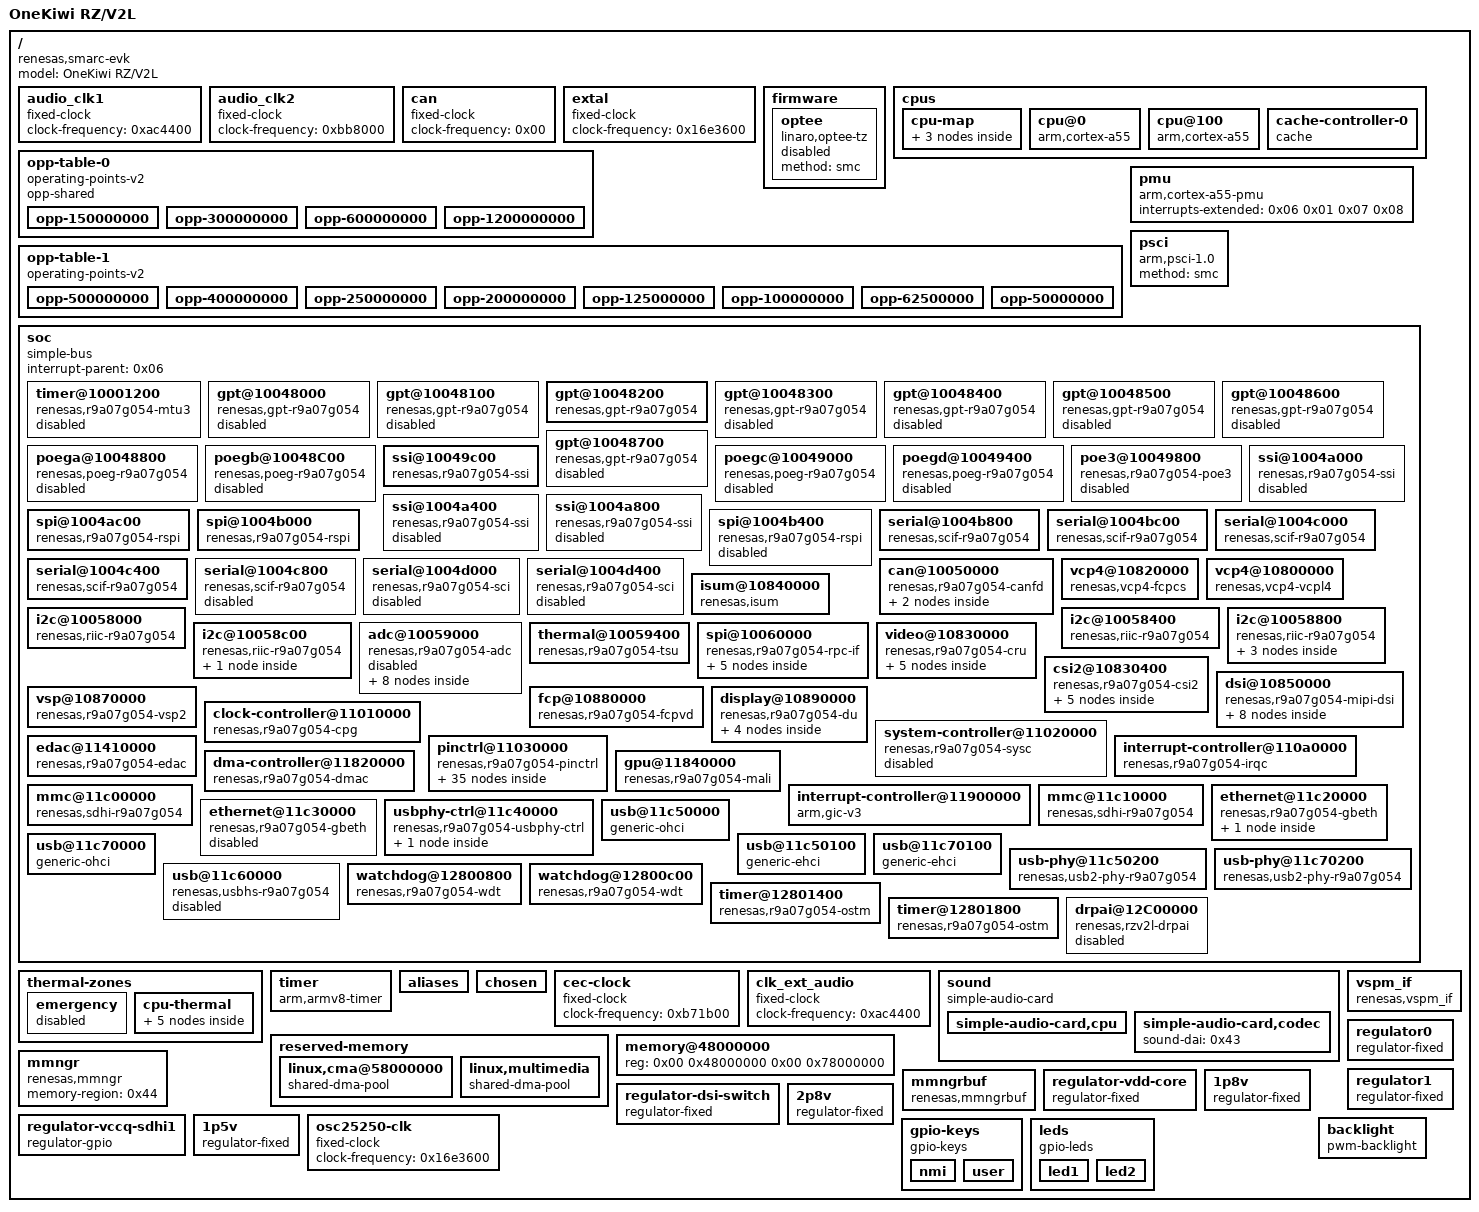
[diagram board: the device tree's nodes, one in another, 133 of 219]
/dts-v1/;

/ {
	compatible = "renesas,smarc-evk", "renesas,r9a07g054l2", "renesas,r9a07g054";
	#address-cells = <0x02>;
	#size-cells = <0x02>;
	model = "OneKiwi RZ/V2L";

	audio_clk1 {
		compatible = "fixed-clock";
		#clock-cells = <0x00>;
		clock-frequency = <0xac4400>;
		phandle = <0x08>;
	};

	audio_clk2 {
		compatible = "fixed-clock";
		#clock-cells = <0x00>;
		clock-frequency = <0xbb8000>;
		phandle = <0x09>;
	};

	can {
		compatible = "fixed-clock";
		#clock-cells = <0x00>;
		clock-frequency = <0x00>;
		phandle = <0x12>;
	};

	extal {
		compatible = "fixed-clock";
		#clock-cells = <0x00>;
		clock-frequency = <0x16e3600>;
		phandle = <0x2d>;
	};

	firmware {

		optee {
			compatible = "linaro,optee-tz";
			method = "smc";
			status = "disabled";
		};
	};

	opp-table-0 {
		compatible = "operating-points-v2";
		opp-shared;
		phandle = <0x05>;

		opp-150000000 {
			opp-hz = <0x00 0x8f0d180>;
			opp-microvolt = <0x10c8e0>;
			clock-latency-ns = <0x493e0>;
		};

		opp-300000000 {
			opp-hz = <0x00 0x11e1a300>;
			opp-microvolt = <0x10c8e0>;
			clock-latency-ns = <0x493e0>;
		};

		opp-600000000 {
			opp-hz = <0x00 0x23c34600>;
			opp-microvolt = <0x10c8e0>;
			clock-latency-ns = <0x493e0>;
		};

		opp-1200000000 {
			opp-hz = <0x00 0x47868c00>;
			opp-microvolt = <0x10c8e0>;
			clock-latency-ns = <0x493e0>;
			opp-suspend;
		};
	};

	cpus {
		#address-cells = <0x01>;
		#size-cells = <0x00>;

		cpu-map {

			cluster0 {

				core0 {
					cpu = <0x01>;
				};

				core1 {
					cpu = <0x02>;
				};
			};
		};

		cpu@0 {
			compatible = "arm,cortex-a55";
			reg = <0x00>;
			device_type = "cpu";
			#cooling-cells = <0x02>;
			next-level-cache = <0x03>;
			enable-method = "psci";
			clocks = <0x04 0x00 0x00>;
			operating-points-v2 = <0x05>;
			phandle = <0x01>;
		};

		cpu@100 {
			compatible = "arm,cortex-a55";
			reg = <0x100>;
			device_type = "cpu";
			next-level-cache = <0x03>;
			enable-method = "psci";
			clocks = <0x04 0x00 0x00>;
			operating-points-v2 = <0x05>;
			phandle = <0x02>;
		};

		cache-controller-0 {
			compatible = "cache";
			cache-unified;
			cache-size = <0x40000>;
			phandle = <0x03>;
		};
	};

	opp-table-1 {
		compatible = "operating-points-v2";
		phandle = <0x2f>;

		opp-500000000 {
			opp-hz = <0x00 0x1dcd6500>;
			opp-microvolt = <0x10c8e0>;
		};

		opp-400000000 {
			opp-hz = <0x00 0x17d78400>;
			opp-microvolt = <0x10c8e0>;
		};

		opp-250000000 {
			opp-hz = <0x00 0xee6b280>;
			opp-microvolt = <0x10c8e0>;
		};

		opp-200000000 {
			opp-hz = <0x00 0xbebc200>;
			opp-microvolt = <0x10c8e0>;
		};

		opp-125000000 {
			opp-hz = <0x00 0x7735940>;
			opp-microvolt = <0x10c8e0>;
		};

		opp-100000000 {
			opp-hz = <0x00 0x5f5e100>;
			opp-microvolt = <0x10c8e0>;
		};

		opp-62500000 {
			opp-hz = <0x00 0x3b9aca0>;
			opp-microvolt = <0x10c8e0>;
		};

		opp-50000000 {
			opp-hz = <0x00 0x2faf080>;
			opp-microvolt = <0x10c8e0>;
		};
	};

	pmu {
		compatible = "arm,cortex-a55-pmu";
		interrupts-extended = <0x06 0x01 0x07 0x08>;
	};

	psci {
		compatible = "arm,psci-1.0", "arm,psci-0.2";
		method = "smc";
	};

	soc {
		compatible = "simple-bus";
		interrupt-parent = <0x06>;
		#address-cells = <0x02>;
		#size-cells = <0x02>;
		ranges;

		timer@10001200 {
			compatible = "renesas,r9a07g054-mtu3", "renesas,rz-mtu3";
			reg = <0x00 0x10001200 0x00 0xb00>;
			interrupts = <0x00 0xaa 0x01 0x00 0xab 0x01 0x00 0xac 0x01 0x00 0xad 0x01 0x00 0xae 0x01 0x00 0xaf 0x01 0x00 0xb0 0x01 0x00 0xb1 0x01 0x00 0xb2 0x01 0x00 0xb3 0x01 0x00 0xb4 0x01 0x00 0xb5 0x01 0x00 0xb6 0x01 0x00 0xb7 0x01 0x00 0xb8 0x01 0x00 0xb9 0x01 0x00 0xba 0x01 0x00 0xbb 0x01 0x00 0xbc 0x01 0x00 0xbd 0x01 0x00 0xbe 0x01 0x00 0xbf 0x01 0x00 0xc0 0x01 0x00 0xc1 0x01 0x00 0xc2 0x01 0x00 0xc3 0x01 0x00 0xc4 0x01 0x00 0xc5 0x01 0x00 0xc6 0x01 0x00 0xc7 0x01 0x00 0xc8 0x01 0x00 0xc9 0x01 0x00 0xca 0x01 0x00 0xcb 0x01 0x00 0xcc 0x01 0x00 0xcd 0x01 0x00 0xce 0x01 0x00 0xcf 0x01 0x00 0xd0 0x01 0x00 0xd1 0x01 0x00 0xd2 0x01 0x00 0xd3 0x01 0x00 0xd4 0x01 0x00 0xd5 0x01>;
			interrupt-names = "tgia0", "tgib0", "tgic0", "tgid0", "tciv0", "tgie0", "tgif0", "tgia1", "tgib1", "tciv1", "tciu1", "tgia2", "tgib2", "tciv2", "tciu2", "tgia3", "tgib3", "tgic3", "tgid3", "tciv3", "tgia4", "tgib4", "tgic4", "tgid4", "tciv4", "tgiu5", "tgiv5", "tgiw5", "tgia6", "tgib6", "tgic6", "tgid6", "tciv6", "tgia7", "tgib7", "tgic7", "tgid7", "tciv7", "tgia8", "tgib8", "tgic8", "tgid8", "tciv8", "tciu8";
			clocks = <0x04 0x01 0x11>;
			power-domains = <0x04>;
			resets = <0x04 0x17>;
			#pwm-cells = <0x02>;
			status = "disabled";
		};

		gpt@10048000 {
			compatible = "renesas,gpt-r9a07g054", "renesas,gpt-r9a07g044";
			reg = <0x00 0x10048000 0x00 0xa4>;
			#pwm-cells = <0x02>;
			interrupts = <0x00 0xda 0x01 0x00 0xdb 0x01 0x00 0xdc 0x01 0x00 0xdd 0x01 0x00 0xde 0x01 0x00 0xdf 0x01 0x00 0xe0 0x01 0x00 0xe1 0x01 0x00 0xe2 0x01 0x00 0xe3 0x01 0x00 0xe4 0x01 0x00 0xe5 0x01 0x00 0xe6 0x01>;
			interrupt-names = "gtcia", "gtcib", "gtcic", "gtcid", "gtcie", "gtcif", "gtciada", "gtciadb", "gtciv", "gtciu", "gtcih", "gtcil", "gtdei";
			clocks = <0x04 0x01 0x13>;
			power-domains = <0x04>;
			resets = <0x04 0x19>;
			status = "disabled";
		};

		gpt@10048100 {
			compatible = "renesas,gpt-r9a07g054", "renesas,gpt-r9a07g044";
			reg = <0x00 0x10048100 0x00 0xa4>;
			#pwm-cells = <0x02>;
			interrupts = <0x00 0xe7 0x01 0x00 0xe8 0x01 0x00 0xe9 0x01 0x00 0xea 0x01 0x00 0xeb 0x01 0x00 0xec 0x01 0x00 0xed 0x01 0x00 0xee 0x01 0x00 0xef 0x01 0x00 0xf0 0x01 0x00 0xf1 0x01 0x00 0xf2 0x01 0x00 0xf3 0x01>;
			interrupt-names = "gtcia", "gtcib", "gtcic", "gtcid", "gtcie", "gtcif", "gtciada", "gtciadb", "gtciv", "gtciu", "gtcih", "gtcil", "gtdei";
			clocks = <0x04 0x01 0x13>;
			power-domains = <0x04>;
			resets = <0x04 0x19>;
			status = "disabled";
		};

		gpt@10048200 {
			compatible = "renesas,gpt-r9a07g054", "renesas,gpt-r9a07g044";
			reg = <0x00 0x10048200 0x00 0xa4>;
			#pwm-cells = <0x02>;
			interrupts = <0x00 0xf4 0x01 0x00 0xf5 0x01 0x00 0xf6 0x01 0x00 0xf7 0x01 0x00 0xf8 0x01 0x00 0xf9 0x01 0x00 0xfa 0x01 0x00 0xfb 0x01 0x00 0xfc 0x01 0x00 0xfd 0x01 0x00 0xfe 0x01 0x00 0xff 0x01 0x00 0x100 0x01>;
			interrupt-names = "gtcia", "gtcib", "gtcic", "gtcid", "gtcie", "gtcif", "gtciada", "gtciadb", "gtciv", "gtciu", "gtcih", "gtcil", "gtdei";
			clocks = <0x04 0x01 0x13>;
			power-domains = <0x04>;
			resets = <0x04 0x19>;
			status = "okay";
			pinctrl-0 = <0x07>;
			pinctrl-names = "default";
			channel = "channel_A";
			phandle = <0x45>;
		};

		gpt@10048300 {
			compatible = "renesas,gpt-r9a07g054", "renesas,gpt-r9a07g044";
			reg = <0x00 0x10048300 0x00 0xa4>;
			#pwm-cells = <0x02>;
			interrupts = <0x00 0x101 0x01 0x00 0x102 0x01 0x00 0x103 0x01 0x00 0x104 0x01 0x00 0x105 0x01 0x00 0x106 0x01 0x00 0x107 0x01 0x00 0x108 0x01 0x00 0x109 0x01 0x00 0x10a 0x01 0x00 0x10b 0x01 0x00 0x10c 0x01 0x00 0x10d 0x01>;
			interrupt-names = "gtcia", "gtcib", "gtcic", "gtcid", "gtcie", "gtcif", "gtciada", "gtciadb", "gtciv", "gtciu", "gtcih", "gtcil", "gtdei";
			clocks = <0x04 0x01 0x13>;
			power-domains = <0x04>;
			resets = <0x04 0x19>;
			status = "disabled";
		};

		gpt@10048400 {
			compatible = "renesas,gpt-r9a07g054", "renesas,gpt-r9a07g044";
			reg = <0x00 0x10048400 0x00 0xa4>;
			#pwm-cells = <0x02>;
			interrupts = <0x00 0x10e 0x01 0x00 0x10f 0x01 0x00 0x110 0x01 0x00 0x111 0x01 0x00 0x112 0x01 0x00 0x113 0x01 0x00 0x114 0x01 0x00 0x115 0x01 0x00 0x116 0x01 0x00 0x117 0x01 0x00 0x118 0x01 0x00 0x119 0x01 0x00 0x11a 0x01>;
			interrupt-names = "gtcia", "gtcib", "gtcic", "gtcid", "gtcie", "gtcif", "gtciada", "gtciadb", "gtciv", "gtciu", "gtcih", "gtcil", "gtdei";
			clocks = <0x04 0x01 0x13>;
			power-domains = <0x04>;
			resets = <0x04 0x19>;
			status = "disabled";
		};

		gpt@10048500 {
			compatible = "renesas,gpt-r9a07g054", "renesas,gpt-r9a07g044";
			reg = <0x00 0x10048500 0x00 0xa4>;
			#pwm-cells = <0x02>;
			interrupts = <0x00 0x11b 0x01 0x00 0x11c 0x01 0x00 0x11d 0x01 0x00 0x11e 0x01 0x00 0x11f 0x01 0x00 0x120 0x01 0x00 0x121 0x01 0x00 0x122 0x01 0x00 0x123 0x01 0x00 0x124 0x01 0x00 0x125 0x01 0x00 0x126 0x01 0x00 0x127 0x01>;
			interrupt-names = "gtcia", "gtcib", "gtcic", "gtcid", "gtcie", "gtcif", "gtciada", "gtciadb", "gtciv", "gtciu", "gtcih", "gtcil", "gtdei";
			clocks = <0x04 0x01 0x13>;
			power-domains = <0x04>;
			resets = <0x04 0x19>;
			status = "disabled";
		};

		gpt@10048600 {
			compatible = "renesas,gpt-r9a07g054", "renesas,gpt-r9a07g044";
			reg = <0x00 0x10048600 0x00 0xa4>;
			#pwm-cells = <0x02>;
			interrupts = <0x00 0x128 0x01 0x00 0x129 0x01 0x00 0x12a 0x01 0x00 0x12b 0x01 0x00 0x12c 0x01 0x00 0x12d 0x01 0x00 0x12e 0x01 0x00 0x12f 0x01 0x00 0x130 0x01 0x00 0x131 0x01 0x00 0x132 0x01 0x00 0x133 0x01 0x00 0x134 0x01>;
			interrupt-names = "gtcia", "gtcib", "gtcic", "gtcid", "gtcie", "gtcif", "gtciada", "gtciadb", "gtciv", "gtciu", "gtcih", "gtcil", "gtdei";
			clocks = <0x04 0x01 0x13>;
			power-domains = <0x04>;
			resets = <0x04 0x19>;
			status = "disabled";
		};

		gpt@10048700 {
			compatible = "renesas,gpt-r9a07g054", "renesas,gpt-r9a07g044";
			reg = <0x00 0x10048700 0x00 0xa4>;
			#pwm-cells = <0x02>;
			interrupts = <0x00 0x135 0x01 0x00 0x136 0x01 0x00 0x137 0x01 0x00 0x138 0x01 0x00 0x139 0x01 0x00 0x13a 0x01 0x00 0x13b 0x01 0x00 0x13c 0x01 0x00 0x13d 0x01 0x00 0x13e 0x01 0x00 0x13f 0x01 0x00 0x140 0x01 0x00 0x141 0x01>;
			interrupt-names = "gtcia", "gtcib", "gtcic", "gtcid", "gtcie", "gtcif", "gtciada", "gtciadb", "gtciv", "gtciu", "gtcih", "gtcil", "gtdei";
			clocks = <0x04 0x01 0x13>;
			power-domains = <0x04>;
			resets = <0x04 0x19>;
			status = "disabled";
		};

		poega@10048800 {
			compatible = "renesas,poeg-r9a07g054", "renesas,poeg-r9a07g044";
			reg = <0x00 0x10048800 0x00 0x04>;
			interrupts = <0x00 0x142 0x04>;
			clocks = <0x04 0x01 0x14>;
			power-domains = <0x04>;
			resets = <0x04 0x1a>;
			status = "disabled";
		};

		poegb@10048C00 {
			compatible = "renesas,poeg-r9a07g054", "renesas,poeg-r9a07g044";
			reg = <0x00 0x10048c00 0x00 0x04>;
			interrupts = <0x00 0x143 0x04>;
			clocks = <0x04 0x01 0x15>;
			power-domains = <0x04>;
			resets = <0x04 0x1b>;
			status = "disabled";
		};

		poegc@10049000 {
			compatible = "renesas,poeg-r9a07g054", "renesas,poeg-r9a07g044";
			reg = <0x00 0x10049000 0x00 0x04>;
			interrupts = <0x00 0x144 0x04>;
			clocks = <0x04 0x01 0x16>;
			power-domains = <0x04>;
			resets = <0x04 0x1c>;
			status = "disabled";
		};

		poegd@10049400 {
			compatible = "renesas,poeg-r9a07g054", "renesas,poeg-r9a07g044";
			reg = <0x00 0x10049400 0x00 0x04>;
			interrupts = <0x00 0x145 0x04>;
			clocks = <0x04 0x01 0x17>;
			power-domains = <0x04>;
			resets = <0x04 0x1d>;
			status = "disabled";
		};

		poe3@10049800 {
			compatible = "renesas,r9a07g054-poe3", "renesas,rz-poe3";
			reg = <0x00 0x10049800 0x00 0x18>;
			interrupts = <0x00 0xd6 0x04 0x00 0xd7 0x04 0x00 0xd8 0x04 0x00 0xd9 0x04>;
			interrupt-names = "oei1", "oei2", "oei3", "oei4";
			clocks = <0x04 0x01 0x12>;
			clock-names = "fck";
			resets = <0x04 0x18>;
			power-domains = <0x04>;
			status = "disabled";
		};

		ssi@10049c00 {
			compatible = "renesas,r9a07g054-ssi", "renesas,rz-ssi";
			reg = <0x00 0x10049c00 0x00 0x400>;
			interrupts = <0x00 0x146 0x04 0x00 0x147 0x01 0x00 0x148 0x01>;
			interrupt-names = "int_req", "dma_rx", "dma_tx";
			clocks = <0x04 0x01 0x3c 0x04 0x01 0x3d 0x08 0x09>;
			clock-names = "ssi", "ssi_sfr", "audio_clk1", "audio_clk2";
			resets = <0x04 0x32>;
			dmas = <0x0a 0x2655 0x0a 0x2656>;
			dma-names = "tx", "rx";
			power-domains = <0x04>;
			#sound-dai-cells = <0x00>;
			status = "okay";
			pinctrl-0 = <0x0b>;
			pinctrl-names = "default";
			phandle = <0x42>;
		};

		ssi@1004a000 {
			compatible = "renesas,r9a07g054-ssi", "renesas,rz-ssi";
			reg = <0x00 0x1004a000 0x00 0x400>;
			interrupts = <0x00 0x14a 0x04 0x00 0x14b 0x01 0x00 0x14c 0x01>;
			interrupt-names = "int_req", "dma_rx", "dma_tx";
			clocks = <0x04 0x01 0x3e 0x04 0x01 0x3f 0x08 0x09>;
			clock-names = "ssi", "ssi_sfr", "audio_clk1", "audio_clk2";
			resets = <0x04 0x33>;
			dmas = <0x0a 0x2659 0x0a 0x265a>;
			dma-names = "tx", "rx";
			power-domains = <0x04>;
			#sound-dai-cells = <0x00>;
			status = "disabled";
		};

		ssi@1004a400 {
			compatible = "renesas,r9a07g054-ssi", "renesas,rz-ssi";
			reg = <0x00 0x1004a400 0x00 0x400>;
			interrupts = <0x00 0x14e 0x04 0x00 0x151 0x01>;
			interrupt-names = "int_req", "dma_rt";
			clocks = <0x04 0x01 0x40 0x04 0x01 0x41 0x08 0x09>;
			clock-names = "ssi", "ssi_sfr", "audio_clk1", "audio_clk2";
			resets = <0x04 0x34>;
			dmas = <0x0a 0x265f>;
			dma-names = "rt";
			power-domains = <0x04>;
			#sound-dai-cells = <0x00>;
			status = "disabled";
		};

		ssi@1004a800 {
			compatible = "renesas,r9a07g054-ssi", "renesas,rz-ssi";
			reg = <0x00 0x1004a800 0x00 0x400>;
			interrupts = <0x00 0x152 0x04 0x00 0x153 0x01 0x00 0x154 0x01>;
			interrupt-names = "int_req", "dma_rx", "dma_tx";
			clocks = <0x04 0x01 0x42 0x04 0x01 0x43 0x08 0x09>;
			clock-names = "ssi", "ssi_sfr", "audio_clk1", "audio_clk2";
			resets = <0x04 0x35>;
			dmas = <0x0a 0x2661 0x0a 0x2662>;
			dma-names = "tx", "rx";
			power-domains = <0x04>;
			#sound-dai-cells = <0x00>;
			status = "disabled";
		};

		spi@1004ac00 {
			compatible = "renesas,r9a07g054-rspi", "renesas,rspi-rz";
			reg = <0x00 0x1004ac00 0x00 0x400>;
			interrupts = <0x00 0x19f 0x04 0x00 0x19d 0x04 0x00 0x19e 0x04>;
			interrupt-names = "error", "rx", "tx";
			clocks = <0x04 0x01 0x59>;
			resets = <0x04 0x49>;
			dmas = <0x0a 0x2e95 0x0a 0x2e96>;
			dma-names = "tx", "rx";
			power-domains = <0x04>;
			num-cs = <0x01>;
			#address-cells = <0x01>;
			#size-cells = <0x00>;
			status = "okay";
			pinctrl-0 = <0x0c>;
			pinctrl-names = "default";
		};

		spi@1004b000 {
			compatible = "renesas,r9a07g054-rspi", "renesas,rspi-rz";
			reg = <0x00 0x1004b000 0x00 0x400>;
			interrupts = <0x00 0x1a2 0x04 0x00 0x1a0 0x04 0x00 0x1a1 0x04>;
			interrupt-names = "error", "rx", "tx";
			clocks = <0x04 0x01 0x5a>;
			resets = <0x04 0x4a>;
			dmas = <0x0a 0x2e99 0x0a 0x2e9a>;
			dma-names = "tx", "rx";
			power-domains = <0x04>;
			num-cs = <0x01>;
			#address-cells = <0x01>;
			#size-cells = <0x00>;
			status = "okay";
			pinctrl-0 = <0x0d>;
			pinctrl-names = "default";
		};

		spi@1004b400 {
			compatible = "renesas,r9a07g054-rspi", "renesas,rspi-rz";
			reg = <0x00 0x1004b400 0x00 0x400>;
			interrupts = <0x00 0x1a5 0x04 0x00 0x1a3 0x04 0x00 0x1a4 0x04>;
			interrupt-names = "error", "rx", "tx";
			clocks = <0x04 0x01 0x5b>;
			resets = <0x04 0x4b>;
			dmas = <0x0a 0x2e9d 0x0a 0x2e9e>;
			dma-names = "tx", "rx";
			power-domains = <0x04>;
			num-cs = <0x01>;
			#address-cells = <0x01>;
			#size-cells = <0x00>;
			status = "disabled";
		};

		serial@1004b800 {
			compatible = "renesas,scif-r9a07g054", "renesas,scif-r9a07g044";
			reg = <0x00 0x1004b800 0x00 0x400>;
			interrupts = <0x00 0x17c 0x04 0x00 0x17e 0x04 0x00 0x17f 0x04 0x00 0x17d 0x04 0x00 0x180 0x04 0x00 0x180 0x04>;
			interrupt-names = "eri", "rxi", "txi", "bri", "dri", "tei";
			clocks = <0x04 0x01 0x51>;
			clock-names = "fck";
			dmas = <0x0a 0x4e79 0x0a 0x4e7a>;
			dma-names = "tx", "rx";
			power-domains = <0x04>;
			resets = <0x04 0x41>;
			status = "okay";
			pinctrl-0 = <0x0e>;
			pinctrl-names = "default";
		};

		serial@1004bc00 {
			compatible = "renesas,scif-r9a07g054", "renesas,scif-r9a07g044";
			reg = <0x00 0x1004bc00 0x00 0x400>;
			interrupts = <0x00 0x181 0x04 0x00 0x183 0x04 0x00 0x184 0x04 0x00 0x182 0x04 0x00 0x185 0x04 0x00 0x185 0x04>;
			interrupt-names = "eri", "rxi", "txi", "bri", "dri", "tei";
			clocks = <0x04 0x01 0x52>;
			clock-names = "fck";
			dmas = <0x0a 0x4e7d 0x0a 0x4e7e>;
			dma-names = "tx", "rx";
			power-domains = <0x04>;
			resets = <0x04 0x42>;
			status = "okay";
			pinctrl-0 = <0x0f>;
			pinctrl-names = "default";
		};

		serial@1004c000 {
			compatible = "renesas,scif-r9a07g054", "renesas,scif-r9a07g044";
			reg = <0x00 0x1004c000 0x00 0x400>;
			interrupts = <0x00 0x186 0x04 0x00 0x188 0x04 0x00 0x189 0x04 0x00 0x187 0x04 0x00 0x18a 0x04 0x00 0x18a 0x04>;
			interrupt-names = "eri", "rxi", "txi", "bri", "dri", "tei";
			clocks = <0x04 0x01 0x53>;
			clock-names = "fck";
			dmas = <0x0a 0x4e81 0x0a 0x4e82>;
			dma-names = "tx", "rx";
			power-domains = <0x04>;
			resets = <0x04 0x43>;
			status = "okay";
			pinctrl-0 = <0x10>;
			pinctrl-names = "default";
			uart-has-rtscts;
		};

		serial@1004c400 {
			compatible = "renesas,scif-r9a07g054", "renesas,scif-r9a07g044";
			reg = <0x00 0x1004c400 0x00 0x400>;
			interrupts = <0x00 0x18b 0x04 0x00 0x18d 0x04 0x00 0x18e 0x04 0x00 0x18c 0x04 0x00 0x18f 0x04 0x00 0x18f 0x04>;
			interrupt-names = "eri", "rxi", "txi", "bri", "dri", "tei";
			clocks = <0x04 0x01 0x54>;
			clock-names = "fck";
			dmas = <0x0a 0x4e85 0x0a 0x4e86>;
			dma-names = "tx", "rx";
			power-domains = <0x04>;
			resets = <0x04 0x44>;
			status = "okay";
			pinctrl-0 = <0x11>;
			pinctrl-names = "default";
		};

		serial@1004c800 {
			compatible = "renesas,scif-r9a07g054", "renesas,scif-r9a07g044";
			reg = <0x00 0x1004c800 0x00 0x400>;
			interrupts = <0x00 0x190 0x04 0x00 0x192 0x04 0x00 0x193 0x04 0x00 0x191 0x04 0x00 0x194 0x04 0x00 0x194 0x04>;
			interrupt-names = "eri", "rxi", "txi", "bri", "dri", "tei";
			clocks = <0x04 0x01 0x55>;
			clock-names = "fck";
			dmas = <0x0a 0x4e89 0x0a 0x4e8a>;
			dma-names = "tx", "rx";
			power-domains = <0x04>;
			resets = <0x04 0x45>;
			status = "disabled";
		};

		serial@1004d000 {
			compatible = "renesas,r9a07g054-sci", "renesas,sci";
			reg = <0x00 0x1004d000 0x00 0x400>;
			interrupts = <0x00 0x195 0x04 0x00 0x196 0x01 0x00 0x197 0x01 0x00 0x198 0x04>;
			interrupt-names = "eri", "rxi", "txi", "tei";
			clocks = <0x04 0x01 0x56>;
			clock-names = "fck";
			power-domains = <0x04>;
			resets = <0x04 0x46>;
			status = "disabled";
		};

		serial@1004d400 {
			compatible = "renesas,r9a07g054-sci", "renesas,sci";
			reg = <0x00 0x1004d400 0x00 0x400>;
			interrupts = <0x00 0x199 0x04 0x00 0x19a 0x01 0x00 0x19b 0x01 0x00 0x19c 0x04>;
			interrupt-names = "eri", "rxi", "txi", "tei";
			clocks = <0x04 0x01 0x57>;
			clock-names = "fck";
			power-domains = <0x04>;
			resets = <0x04 0x47>;
			status = "disabled";
		};

		can@10050000 {
			compatible = "renesas,r9a07g054-canfd", "renesas,rzg2l-canfd";
			reg = <0x00 0x10050000 0x00 0x8000>;
			interrupts = <0x00 0x1aa 0x04 0x00 0x1ab 0x04 0x00 0x1a6 0x04 0x00 0x1a8 0x04 0x00 0x1ac 0x04 0x00 0x1a7 0x04 0x00 0x1a9 0x04 0x00 0x1ad 0x04>;
			interrupt-names = "g_err", "g_recc", "ch0_err", "ch0_rec", "ch0_trx", "ch1_err", "ch1_rec", "ch1_trx";
			clocks = <0x04 0x01 0x5c 0x04 0x00 0x16 0x12>;
			clock-names = "fck", "canfd", "can_clk";
			assigned-clocks = <0x04 0x00 0x16>;
			assigned-clock-rates = <0x2faf080>;
			resets = <0x04 0x4c 0x04 0x4d>;
			reset-names = "rstp_n", "rstc_n";
			power-domains = <0x04>;
			status = "okay";
			pinctrl-0 = <0x13 0x14>;
			pinctrl-names = "default";

			channel0 {
				status = "okay";
			};

			channel1 {
				status = "okay";
			};
		};

		vcp4@10820000 {
			compatible = "renesas,vcp4-fcpcs";
			reg = <0x00 0x10820000 0x00 0x200>;
			renesas,#ch = <0x00>;
		};

		vcp4@10800000 {
			compatible = "renesas,vcp4-vcpl4";
			reg = <0x00 0x10800000 0x00 0x200 0x00 0x10810200 0x00 0x200>;
			interrupts = <0x00 0xa1 0x04 0x00 0xa2 0x04>;
			clocks = <0x04 0x01 0x2d 0x04 0x01 0x2e>;
			power-domains = <0x04>;
			resets = <0x04 0x29 0x04 0x2a>;
			renesas,#ch = <0x00>;
			renesas,#fcp_ch = <0x00>;
		};

		isum@10840000 {
			compatible = "renesas,isum";
			reg = <0x00 0x10840000 0x00 0x1f4>;
			interrupts = <0x00 0x9d 0x04 0x00 0x9e 0x04 0x00 0x9f 0x04 0x00 0xa0 0x04>;
			clocks = <0x04 0x01 0x2b 0x04 0x01 0x2c>;
			clock-names = "isu_aclk", "isu_pclk";
			resets = <0x04 0x27 0x04 0x28>;
			reset-names = "aresetn", "presetn";
			renesas,#ch = <0x00>;
			renesas,#rpf = <0x01>;
			renesas,#wpf = <0x01>;
			renesas,has-rs;
			power-domains = <0x04>;
		};

		i2c@10058000 {
			#address-cells = <0x01>;
			#size-cells = <0x00>;
			compatible = "renesas,riic-r9a07g054", "renesas,riic-rz";
			reg = <0x00 0x10058000 0x00 0x400>;
			interrupts = <0x00 0x15e 0x04 0x00 0x15c 0x01 0x00 0x15d 0x01 0x00 0x160 0x04 0x00 0x161 0x04 0x00 0x15f 0x04 0x00 0x162 0x04 0x00 0x163 0x04>;
			interrupt-names = "tei", "ri", "ti", "spi", "sti", "naki", "ali", "tmoi";
			clocks = <0x04 0x01 0x4d>;
			clock-frequency = <0x186a0>;
			resets = <0x04 0x3d>;
			power-domains = <0x04>;
			status = "okay";
			pinctrl-0 = <0x15>;
			pinctrl-names = "default";
		};

		i2c@10058400 {
			#address-cells = <0x01>;
			#size-cells = <0x00>;
			compatible = "renesas,riic-r9a07g054", "renesas,riic-rz";
			reg = <0x00 0x10058400 0x00 0x400>;
			interrupts = <0x00 0x166 0x04 0x00 0x164 0x01 0x00 0x165 0x01 0x00 0x168 0x04 0x00 0x169 0x04 0x00 0x167 0x04 0x00 0x16a 0x04 0x00 0x16b 0x04>;
			interrupt-names = "tei", "ri", "ti", "spi", "sti", "naki", "ali", "tmoi";
			clocks = <0x04 0x01 0x4e>;
			clock-frequency = <0x186a0>;
			resets = <0x04 0x3e>;
			power-domains = <0x04>;
			status = "okay";
			pinctrl-0 = <0x16>;
			pinctrl-names = "default";
		};

		i2c@10058800 {
			#address-cells = <0x01>;
			#size-cells = <0x00>;
			compatible = "renesas,riic-r9a07g054", "renesas,riic-rz";
			reg = <0x00 0x10058800 0x00 0x400>;
			interrupts = <0x00 0x16e 0x04 0x00 0x16c 0x01 0x00 0x16d 0x01 0x00 0x170 0x04 0x00 0x171 0x04 0x00 0x16f 0x04 0x00 0x172 0x04 0x00 0x173 0x04>;
			interrupt-names = "tei", "ri", "ti", "spi", "sti", "naki", "ali", "tmoi";
			clocks = <0x04 0x01 0x4f>;
			clock-frequency = <0x186a0>;
			resets = <0x04 0x3f>;
			power-domains = <0x04>;
			status = "okay";
			pinctrl-0 = <0x17>;
			pinctrl-names = "default";

			camera@3c {
				compatible = "ovti,ov5645";
				reg = <0x3c>;
				clocks = <0x18>;
				clock-frequency = <0x16e3600>;
				vdddo-supply = <0x19>;
				vdda-supply = <0x1a>;
				vddd-supply = <0x1b>;
				enable-gpios = <0x1c 0x59 0x00>;
				reset-gpios = <0x1c 0x60 0x01>;

				port {

					endpoint {
						clock-lanes = <0x00>;
						data-lanes = <0x01 0x02>;
						remote-endpoint = <0x1d>;
						phandle = <0x24>;
					};
				};
			};
		};

		i2c@10058c00 {
			#address-cells = <0x01>;
			#size-cells = <0x00>;
			compatible = "renesas,riic-r9a07g054", "renesas,riic-rz";
			reg = <0x00 0x10058c00 0x00 0x400>;
			interrupts = <0x00 0x176 0x04 0x00 0x174 0x01 0x00 0x175 0x01 0x00 0x178 0x04 0x00 0x179 0x04 0x00 0x177 0x04 0x00 0x17a 0x04 0x00 0x17b 0x04>;
			interrupt-names = "tei", "ri", "ti", "spi", "sti", "naki", "ali", "tmoi";
			clocks = <0x04 0x01 0x50>;
			clock-frequency = <0x186a0>;
			resets = <0x04 0x40>;
			power-domains = <0x04>;
			status = "okay";
			pinctrl-0 = <0x1e>;
			pinctrl-names = "default";

			audio-codec@a {
				#sound-dai-cells = <0x00>;
				compatible = "fsl,sgtl5000";
				reg = <0x0a>;
				VDDIO-supply = <0x1f>;
				VDDA-supply = <0x1f>;
				VDDD-supply = <0x20>;
				clocks = <0x21>;
				phandle = <0x43>;
			};
		};

		adc@10059000 {
			compatible = "renesas,r9a07g054-adc", "renesas,rzg2l-adc";
			reg = <0x00 0x10059000 0x00 0x400>;
			interrupts = <0x00 0x15b 0x01>;
			clocks = <0x04 0x01 0x5e 0x04 0x01 0x5f>;
			clock-names = "adclk", "pclk";
			resets = <0x04 0x51 0x04 0x52>;
			reset-names = "presetn", "adrst-n";
			power-domains = <0x04>;
			status = "disabled";
			#address-cells = <0x01>;
			#size-cells = <0x00>;

			channel@0 {
				reg = <0x00>;
			};

			channel@1 {
				reg = <0x01>;
			};

			channel@2 {
				reg = <0x02>;
			};

			channel@3 {
				reg = <0x03>;
			};

			channel@4 {
				reg = <0x04>;
			};

			channel@5 {
				reg = <0x05>;
			};

			channel@6 {
				reg = <0x06>;
			};

			channel@7 {
				reg = <0x07>;
			};
		};

		thermal@10059400 {
			compatible = "renesas,r9a07g054-tsu", "renesas,rzg2l-tsu";
			reg = <0x00 0x10059400 0x00 0x400>;
			clocks = <0x04 0x01 0x60>;
			resets = <0x04 0x53>;
			power-domains = <0x04>;
			#thermal-sensor-cells = <0x01>;
			phandle = <0x3f>;
		};

		spi@10060000 {
			compatible = "renesas,r9a07g054-rpc-if", "renesas,rzg2l-rpc-if";
			reg = <0x00 0x10060000 0x00 0x10000 0x00 0x20000000 0x00 0x10000000 0x00 0x10070000 0x00 0x10000>;
			reg-names = "regs", "dirmap", "wbuf";
			interrupts = <0x00 0x29 0x04>;
			clocks = <0x04 0x01 0x1e 0x04 0x01 0x1f>;
			resets = <0x04 0x21>;
			power-domains = <0x04>;
			#address-cells = <0x01>;
			#size-cells = <0x00>;
			status = "okay";
			pinctrl-0 = <0x22>;
			pinctrl-names = "default";

			flash@0 {
				compatible = "micron,mt25qu512a", "jedec,spi-nor";
				reg = <0x00>;
				m25p,fast-read;
				spi-max-frequency = <0x2faf080>;
				spi-rx-bus-width = <0x04>;
				spi-tx-bus-width = <0x04>;

				partitions {
					compatible = "fixed-partitions";
					#address-cells = <0x01>;
					#size-cells = <0x01>;

					partition@0 {
						label = "bl2";
						reg = <0x00 0x1c000>;
					};

					partition@1d000 {
						label = "fip";
						reg = <0x1d000 0x1fe3000>;
					};

					partition@2000000 {
						label = "user";
						reg = <0x2000000 0x2000000>;
					};
				};
			};
		};

		video@10830000 {
			compatible = "renesas,r9a07g054-cru", "renesas,rzg2l-cru";
			reg = <0x00 0x10830000 0x00 0x400>;
			clocks = <0x04 0x01 0x30 0x04 0x01 0x31 0x04 0x01 0x32>;
			clock-names = "video", "apb", "axi";
			interrupts = <0x00 0xa7 0x04 0x00 0xa8 0x04 0x00 0xa9 0x04>;
			interrupt-names = "image_conv", "image_conv_err", "axi_mst_err";
			resets = <0x04 0x2c 0x04 0x2d>;
			reset-names = "presetn", "aresetn";
			power-domains = <0x04>;
			status = "okay";

			ports {
				#address-cells = <0x01>;
				#size-cells = <0x00>;

				port@0 {
					#address-cells = <0x01>;
					#size-cells = <0x00>;
					reg = <0x00>;

					endpoint@0 {
						reg = <0x00>;
					};
				};

				port@1 {
					#address-cells = <0x01>;
					#size-cells = <0x00>;
					reg = <0x01>;

					endpoint@0 {
						reg = <0x00>;
						remote-endpoint = <0x23>;
						phandle = <0x25>;
					};
				};
			};
		};

		csi2@10830400 {
			compatible = "renesas,r9a07g054-csi2", "renesas,rzg2l-csi2";
			reg = <0x00 0x10830400 0x00 0xfc00>;
			interrupts = <0x00 0xa6 0x04>;
			clocks = <0x04 0x01 0x2f 0x04 0x01 0x30 0x04 0x01 0x31>;
			clock-names = "system", "video", "apb";
			resets = <0x04 0x2c 0x04 0x2b>;
			reset-names = "presetn", "cmn-rstb";
			power-domains = <0x04>;
			status = "okay";

			ports {
				#address-cells = <0x01>;
				#size-cells = <0x00>;

				port@0 {
					reg = <0x00>;

					endpoint {
						clock-lanes = <0x00>;
						data-lanes = <0x01 0x02>;
						remote-endpoint = <0x24>;
						phandle = <0x1d>;
					};
				};

				port@1 {
					#address-cells = <0x01>;
					#size-cells = <0x00>;
					reg = <0x01>;

					endpoint@0 {
						reg = <0x00>;
						remote-endpoint = <0x25>;
						phandle = <0x23>;
					};
				};
			};
		};

		dsi@10850000 {
			compatible = "renesas,r9a07g054-mipi-dsi", "renesas,rzg2l-mipi-dsi";
			reg = <0x00 0x10850000 0x00 0x20000>;
			interrupts = <0x00 0x8e 0x04 0x00 0x8f 0x04 0x00 0x90 0x04 0x00 0x91 0x04 0x00 0x92 0x04 0x00 0x93 0x04 0x00 0x94 0x04>;
			interrupt-names = "seq0", "seq1", "vin1", "rcv", "ferr", "ppi", "debug";
			clocks = <0x04 0x01 0x33 0x04 0x01 0x34 0x04 0x01 0x35 0x04 0x01 0x36 0x04 0x01 0x37 0x04 0x01 0x38>;
			clock-names = "pllclk", "sysclk", "aclk", "pclk", "vclk", "lpclk";
			resets = <0x04 0x2e 0x04 0x2f 0x04 0x30>;
			reset-names = "rst", "arst", "prst";
			power-domains = <0x04>;
			status = "okay";
			#address-cells = <0x01>;
			#size-cells = <0x00>;

			ports {
				#address-cells = <0x01>;
				#size-cells = <0x00>;

				port@0 {
					reg = <0x00>;

					endpoint {
						remote-endpoint = <0x26>;
						phandle = <0x2c>;
					};
				};

				port@1 {
					reg = <0x01>;

					endpoint {
						remote-endpoint = <0x27>;
						data-lanes = <0x01 0x02>;
						phandle = <0x29>;
					};
				};
			};

			panel@0 {
				compatible = "newhaven,nhd35-640480ef";
				reg = <0x00>;
				reset-gpios = <0x1c 0x154 0x01>;
				backlight = <0x28>;
				status = "okay";

				port {

					endpoint {
						remote-endpoint = <0x29>;
						phandle = <0x27>;
					};
				};
			};
		};

		vsp@10870000 {
			compatible = "renesas,r9a07g054-vsp2", "renesas,r9a07g044-vsp2";
			reg = <0x00 0x10870000 0x00 0x10000>;
			interrupts = <0x00 0x95 0x04>;
			clocks = <0x04 0x01 0x39 0x04 0x01 0x3a 0x04 0x01 0x3b>;
			clock-names = "aclk", "pclk", "vclk";
			power-domains = <0x04>;
			resets = <0x04 0x31>;
			renesas,fcp = <0x2a>;
			phandle = <0x2b>;
		};

		fcp@10880000 {
			compatible = "renesas,r9a07g054-fcpvd", "renesas,fcpv";
			reg = <0x00 0x10880000 0x00 0x10000>;
			clocks = <0x04 0x01 0x39 0x04 0x01 0x3a 0x04 0x01 0x3b>;
			clock-names = "aclk", "pclk", "vclk";
			power-domains = <0x04>;
			resets = <0x04 0x31>;
			phandle = <0x2a>;
		};

		display@10890000 {
			compatible = "renesas,r9a07g054-du", "renesas,r9a07g044-du";
			reg = <0x00 0x10890000 0x00 0x10000>;
			interrupts = <0x00 0x98 0x04>;
			clocks = <0x04 0x01 0x39 0x04 0x01 0x3a 0x04 0x01 0x3b>;
			clock-names = "aclk", "pclk", "vclk";
			power-domains = <0x04>;
			resets = <0x04 0x31>;
			renesas,vsps = <0x2b 0x00>;
			status = "okay";
			dsi-lanes = <0x02>;

			ports {
				#address-cells = <0x01>;
				#size-cells = <0x00>;

				port@0 {
					reg = <0x00>;

					endpoint {
						remote-endpoint = <0x2c>;
						phandle = <0x26>;
					};
				};

				port@1 {
					reg = <0x01>;
				};
			};
		};

		clock-controller@11010000 {
			compatible = "renesas,r9a07g054-cpg";
			reg = <0x00 0x11010000 0x00 0x10000>;
			clocks = <0x2d>;
			clock-names = "extal";
			#clock-cells = <0x02>;
			#reset-cells = <0x01>;
			#power-domain-cells = <0x00>;
			phandle = <0x04>;
		};

		system-controller@11020000 {
			compatible = "renesas,r9a07g054-sysc", "syscon";
			reg = <0x00 0x11020000 0x00 0x10000>;
			interrupts = <0x00 0x2a 0x04 0x00 0x2b 0x04 0x00 0x2c 0x04 0x00 0x2d 0x04>;
			interrupt-names = "lpm_int", "ca55stbydone_int", "cm33stbyr_int", "ca55_deny";
			#renesas,sysc-signal-cells = <0x02>;
			status = "disabled";
			phandle = <0x3e>;
		};

		pinctrl@11030000 {
			compatible = "renesas,r9a07g054-pinctrl", "renesas,r9a07g044-pinctrl";
			reg = <0x00 0x11030000 0x00 0x10000>;
			gpio-controller;
			#gpio-cells = <0x02>;
			#address-cells = <0x02>;
			#interrupt-cells = <0x02>;
			interrupt-parent = <0x2e>;
			interrupt-controller;
			gpio-ranges = <0x1c 0x00 0x00 0x188>;
			clocks = <0x04 0x01 0x5d>;
			power-domains = <0x04>;
			resets = <0x04 0x4e 0x04 0x4f 0x04 0x50>;
			phandle = <0x1c>;

			can0 {
				pinmux = <0x20058 0x20051>;
				phandle = <0x13>;
			};

			can1 {
				pinmux = <0x20068 0x20061>;
				phandle = <0x14>;
			};

			eth0 {
				phandle = <0x33>;

				txc {
					pinmux = <0x100a0>;
					power-source = <0x708>;
					output-enable;
				};

				mux {
					pinmux = <0x100e1 0x100d9 0x100e0 0x100a1 0x100a2 0x100a8 0x100a9 0x100b0 0x100c0 0x100c1 0x100c8 0x100c9 0x100d0 0x100d1>;
					power-source = <0x708>;
				};
			};

			gpt2 {
				pinmux = <0x30010>;
				phandle = <0x07>;
			};

			i2c0 {
				pins = "RIIC0_SDA", "RIIC0_SCL";
				input-enable;
				phandle = <0x15>;
			};

			i2c1 {
				pins = "RIIC1_SDA", "RIIC1_SCL";
				input-enable;
				phandle = <0x16>;
			};

			i2c2 {
				pinmux = <0x20019 0x20018>;
				phandle = <0x17>;
			};

			i2c3 {
				pinmux = <0x30091 0x30090>;
				phandle = <0x1e>;
			};

			scif0 {
				pinmux = <0x10130 0x10131>;
				phandle = <0x0e>;
			};

			scif1 {
				pinmux = <0x10141 0x10140>;
				phandle = <0x0f>;
			};

			scif2 {
				pinmux = <0x10183 0x10184 0x10181 0x10180>;
				phandle = <0x10>;
			};

			scif3 {
				pinmux = <0x50001 0x50000>;
				phandle = <0x11>;
			};

			sd0emmc {
				phandle = <0x31>;

				sd0_emmc_data {
					pins = "SD0_DATA0", "SD0_DATA1", "SD0_DATA2", "SD0_DATA3", "SD0_DATA4", "SD0_DATA5", "SD0_DATA6", "SD0_DATA7";
					power-source = <0x708>;
				};

				sd0_emmc_ctrl {
					pins = "SD0_CLK", "SD0_CMD";
					power-source = <0x708>;
				};

				sd0_emmc_rst {
					pins = "SD0_RST#";
					power-source = <0x708>;
				};
			};

			sd1 {
				phandle = <0x32>;

				sd1_data {
					pins = "SD1_DATA0", "SD1_DATA1", "SD1_DATA2", "SD1_DATA3";
					power-source = <0xce4>;
				};

				sd1_ctrl {
					pins = "SD1_CLK", "SD1_CMD";
					power-source = <0xce4>;
				};

				sd1_mux {
					pinmux = <0x10098>;
				};
			};

			sd1_uhs {

				sd1_data_uhs {
					pins = "SD1_DATA0", "SD1_DATA1", "SD1_DATA2", "SD1_DATA3";
					power-source = <0x708>;
				};

				sd1_ctrl_uhs {
					pins = "SD1_CLK", "SD1_CMD";
					power-source = <0x708>;
				};

				sd1_mux_uhs {
					pinmux = <0x10098>;
				};
			};

			qspi0 {
				phandle = <0x22>;

				qspi0-data {
					pins = "QSPI0_IO0", "QSPI0_IO1", "QSPI0_IO2", "QSPI0_IO3";
					power-source = <0x708>;
				};

				qspi0-ctrl {
					pins = "QSPI0_SPCLK", "QSPI0_SSL", "QSPI_RESET#";
					power-source = <0x708>;
				};
			};

			sound_clk {
				pins = "AUDIO_CLK1", "AUDIO_CLK2";
				input-enable;
			};

			spi0 {
				pinmux = <0x50178 0x5017a 0x50179 0x5017b>;
				phandle = <0x0c>;
			};

			spi1 {
				pinmux = <0x10160 0x10161 0x10162 0x10163>;
				phandle = <0x0d>;
			};

			ssi0 {
				pinmux = <0x10168 0x10169 0x1016a 0x1016b>;
				phandle = <0x0b>;
			};

			usb0 {
				pinmux = <0x10020 0x10028 0x10029>;
				phandle = <0x3b>;
			};

			usb1 {
				pinmux = <0x10150 0x10151>;
				phandle = <0x3d>;
			};
		};

		interrupt-controller@110a0000 {
			compatible = "renesas,r9a07g054-irqc", "renesas,rzg2l-irqc";
			#interrupt-cells = <0x02>;
			#address-cells = <0x00>;
			interrupt-controller;
			reg = <0x00 0x110a0000 0x00 0x10000>;
			interrupts = <0x00 0x00 0x04 0x00 0x01 0x04 0x00 0x02 0x04 0x00 0x03 0x04 0x00 0x04 0x04 0x00 0x05 0x04 0x00 0x06 0x04 0x00 0x07 0x04 0x00 0x08 0x04 0x00 0x1bc 0x04 0x00 0x1bd 0x04 0x00 0x1be 0x04 0x00 0x1bf 0x04 0x00 0x1c0 0x04 0x00 0x1c1 0x04 0x00 0x1c2 0x04 0x00 0x1c3 0x04 0x00 0x1c4 0x04 0x00 0x1c5 0x04 0x00 0x1c6 0x04 0x00 0x1c7 0x04 0x00 0x1c8 0x04 0x00 0x1c9 0x04 0x00 0x1ca 0x04 0x00 0x1cb 0x04 0x00 0x1cc 0x04 0x00 0x1cd 0x04 0x00 0x1ce 0x04 0x00 0x1cf 0x04 0x00 0x1d0 0x04 0x00 0x1d1 0x04 0x00 0x1d2 0x04 0x00 0x1d3 0x04 0x00 0x1d4 0x04 0x00 0x1d5 0x04 0x00 0x1d6 0x04 0x00 0x1d7 0x04 0x00 0x1d8 0x04 0x00 0x1d9 0x04 0x00 0x1da 0x04 0x00 0x1db 0x04 0x00 0x19 0x01 0x00 0x22 0x01 0x00 0x23 0x01 0x00 0x24 0x01 0x00 0x25 0x01 0x00 0x26 0x01 0x00 0x27 0x01>;
			interrupt-names = "nmi", "irq0", "irq1", "irq2", "irq3", "irq4", "irq5", "irq6", "irq7", "tint0", "tint1", "tint2", "tint3", "tint4", "tint5", "tint6", "tint7", "tint8", "tint9", "tint10", "tint11", "tint12", "tint13", "tint14", "tint15", "tint16", "tint17", "tint18", "tint19", "tint20", "tint21", "tint22", "tint23", "tint24", "tint25", "tint26", "tint27", "tint28", "tint29", "tint30", "tint31", "bus-err", "ec7tie1-0", "ec7tie2-0", "ec7tiovf-0", "ec7tie1-1", "ec7tie2-1", "ec7tiovf-1";
			clocks = <0x04 0x01 0x08 0x04 0x01 0x09>;
			clock-names = "clk", "pclk";
			power-domains = <0x04>;
			resets = <0x04 0x0f>;
			phandle = <0x2e>;
		};

		edac@11410000 {
			compatible = "renesas,r9a07g054-edac";
			reg = <0x00 0x11410000 0x00 0x10000>;
			interrupts = <0x00 0x28 0x04>;
			interrupt-names = "ecc_irq";
		};

		dma-controller@11820000 {
			compatible = "renesas,r9a07g054-dmac", "renesas,rz-dmac";
			reg = <0x00 0x11820000 0x00 0x10000 0x00 0x11830000 0x00 0x10000>;
			interrupts = <0x00 0x8d 0x01 0x00 0x7d 0x01 0x00 0x7e 0x01 0x00 0x7f 0x01 0x00 0x80 0x01 0x00 0x81 0x01 0x00 0x82 0x01 0x00 0x83 0x01 0x00 0x84 0x01 0x00 0x85 0x01 0x00 0x86 0x01 0x00 0x87 0x01 0x00 0x88 0x01 0x00 0x89 0x01 0x00 0x8a 0x01 0x00 0x8b 0x01 0x00 0x8c 0x01>;
			interrupt-names = "error", "ch0", "ch1", "ch2", "ch3", "ch4", "ch5", "ch6", "ch7", "ch8", "ch9", "ch10", "ch11", "ch12", "ch13", "ch14", "ch15";
			clocks = <0x04 0x01 0x0c 0x04 0x01 0x0d>;
			clock-names = "main", "register";
			power-domains = <0x04>;
			resets = <0x04 0x11 0x04 0x12>;
			reset-names = "arst", "rst_async";
			#dma-cells = <0x01>;
			dma-channels = <0x10>;
			phandle = <0x0a>;
		};

		gpu@11840000 {
			compatible = "renesas,r9a07g054-mali", "arm,mali-bifrost";
			reg = <0x00 0x11840000 0x00 0x10000>;
			interrupts = <0x00 0x9a 0x04 0x00 0x9b 0x04 0x00 0x99 0x04 0x00 0x9c 0x04>;
			interrupt-names = "job", "mmu", "gpu", "event";
			clocks = <0x04 0x01 0x28 0x04 0x01 0x29 0x04 0x01 0x2a>;
			clock-names = "gpu", "bus", "bus_ace";
			resets = <0x04 0x24 0x04 0x25 0x04 0x26>;
			reset-names = "rst", "axi_rst", "ace_rst";
			operating-points-v2 = <0x2f>;
			status = "okay";
			mali-supply = <0x30>;
		};

		interrupt-controller@11900000 {
			compatible = "arm,gic-v3";
			#interrupt-cells = <0x03>;
			#address-cells = <0x00>;
			interrupt-controller;
			reg = <0x00 0x11900000 0x00 0x40000 0x00 0x11940000 0x00 0x60000>;
			interrupts = <0x01 0x09 0x08>;
			phandle = <0x06>;
		};

		mmc@11c00000 {
			compatible = "renesas,sdhi-r9a07g054", "renesas,rcar-gen3-sdhi";
			reg = <0x00 0x11c00000 0x00 0x10000>;
			interrupts = <0x00 0x68 0x04 0x00 0x69 0x04>;
			clocks = <0x04 0x01 0x20 0x04 0x01 0x22 0x04 0x01 0x21 0x04 0x01 0x23>;
			clock-names = "core", "clkh", "cd", "aclk";
			resets = <0x04 0x22>;
			power-domains = <0x04>;
			status = "okay";
			pinctrl-names = "default", "state_uhs";
			pinctrl-0 = <0x31>;
			pinctrl-1 = <0x31>;
			vmmc-supply = <0x1f>;
			vqmmc-supply = <0x20>;
			bus-width = <0x08>;
			mmc-hs200-1_8v;
			non-removable;
			fixed-emmc-driver-type = <0x01>;
		};

		mmc@11c10000 {
			compatible = "renesas,sdhi-r9a07g054", "renesas,rcar-gen3-sdhi";
			reg = <0x00 0x11c10000 0x00 0x10000>;
			interrupts = <0x00 0x6a 0x04 0x00 0x6b 0x04>;
			clocks = <0x04 0x01 0x24 0x04 0x01 0x26 0x04 0x01 0x25 0x04 0x01 0x27>;
			clock-names = "core", "clkh", "cd", "aclk";
			resets = <0x04 0x23>;
			power-domains = <0x04>;
			status = "okay";
			pinctrl-0 = <0x32>;
			pinctrl-names = "default";
			vmmc-supply = <0x1f>;
			bus-width = <0x04>;
		};

		ethernet@11c20000 {
			compatible = "renesas,r9a07g054-gbeth", "renesas,rzg2l-gbeth";
			reg = <0x00 0x11c20000 0x00 0x10000>;
			interrupts = <0x00 0x54 0x04 0x00 0x55 0x04 0x00 0x56 0x04>;
			interrupt-names = "mux", "fil", "arp_ns";
			phy-mode = "rgmii-id";
			clocks = <0x04 0x01 0x49 0x04 0x01 0x4a 0x04 0x00 0x0e>;
			clock-names = "axi", "chi", "refclk";
			resets = <0x04 0x3b>;
			power-domains = <0x04>;
			#address-cells = <0x01>;
			#size-cells = <0x00>;
			status = "okay";
			pinctrl-0 = <0x33>;
			pinctrl-names = "default";
			phy-handle = <0x34>;

			ethernet-phy@7 {
				compatible = "ethernet-phy-id0022.1640", "ethernet-phy-ieee802.3-c22";
				reg = <0x07>;
				rxc-skew-psec = <0x960>;
				txc-skew-psec = <0x960>;
				rxdv-skew-psec = <0x00>;
				txen-skew-psec = <0x00>;
				rxd0-skew-psec = <0x00>;
				rxd1-skew-psec = <0x00>;
				rxd2-skew-psec = <0x00>;
				rxd3-skew-psec = <0x00>;
				txd0-skew-psec = <0x00>;
				txd1-skew-psec = <0x00>;
				txd2-skew-psec = <0x00>;
				txd3-skew-psec = <0x00>;
				interrupt-parent = <0x1c>;
				interrupts = <0x08 0x08>;
				phandle = <0x34>;
			};
		};

		ethernet@11c30000 {
			compatible = "renesas,r9a07g054-gbeth", "renesas,rzg2l-gbeth";
			reg = <0x00 0x11c30000 0x00 0x10000>;
			interrupts = <0x00 0x57 0x04 0x00 0x58 0x04 0x00 0x59 0x04>;
			interrupt-names = "mux", "fil", "arp_ns";
			phy-mode = "rgmii";
			clocks = <0x04 0x01 0x4b 0x04 0x01 0x4c 0x04 0x00 0x0e>;
			clock-names = "axi", "chi", "refclk";
			resets = <0x04 0x3c>;
			power-domains = <0x04>;
			#address-cells = <0x01>;
			#size-cells = <0x00>;
			status = "disabled";
		};

		usbphy-ctrl@11c40000 {
			compatible = "renesas,r9a07g054-usbphy-ctrl", "renesas,rzg2l-usbphy-ctrl";
			reg = <0x00 0x11c40000 0x00 0x10000>;
			clocks = <0x04 0x01 0x48>;
			resets = <0x04 0x3a>;
			power-domains = <0x04>;
			#reset-cells = <0x01>;
			status = "okay";
			phandle = <0x35>;

			regulator-vbus {
				regulator-name = "vbus";
				phandle = <0x3c>;
			};
		};

		usb@11c50000 {
			compatible = "generic-ohci";
			reg = <0x00 0x11c50000 0x00 0x100>;
			interrupts = <0x00 0x5b 0x04>;
			clocks = <0x04 0x01 0x48 0x04 0x01 0x45>;
			resets = <0x35 0x00 0x04 0x37>;
			phys = <0x36 0x01>;
			phy-names = "usb";
			power-domains = <0x04>;
			status = "okay";
			dr_mode = "otg";
			memory-region = <0x37>;
			phandle = <0x39>;
		};

		usb@11c70000 {
			compatible = "generic-ohci";
			reg = <0x00 0x11c70000 0x00 0x100>;
			interrupts = <0x00 0x60 0x04>;
			clocks = <0x04 0x01 0x48 0x04 0x01 0x46>;
			resets = <0x35 0x01 0x04 0x38>;
			phys = <0x38 0x01>;
			phy-names = "usb";
			power-domains = <0x04>;
			status = "okay";
			memory-region = <0x37>;
			phandle = <0x3a>;
		};

		usb@11c50100 {
			compatible = "generic-ehci";
			reg = <0x00 0x11c50100 0x00 0x100>;
			interrupts = <0x00 0x5c 0x04>;
			clocks = <0x04 0x01 0x48 0x04 0x01 0x45>;
			resets = <0x35 0x00 0x04 0x37>;
			phys = <0x36 0x02>;
			phy-names = "usb";
			companion = <0x39>;
			power-domains = <0x04>;
			status = "okay";
			dr_mode = "otg";
			memory-region = <0x37>;
		};

		usb@11c70100 {
			compatible = "generic-ehci";
			reg = <0x00 0x11c70100 0x00 0x100>;
			interrupts = <0x00 0x61 0x04>;
			clocks = <0x04 0x01 0x48 0x04 0x01 0x46>;
			resets = <0x35 0x01 0x04 0x38>;
			phys = <0x38 0x02>;
			phy-names = "usb";
			companion = <0x3a>;
			power-domains = <0x04>;
			status = "okay";
			memory-region = <0x37>;
		};

		usb-phy@11c50200 {
			compatible = "renesas,usb2-phy-r9a07g054", "renesas,rzg2l-usb2-phy";
			reg = <0x00 0x11c50200 0x00 0x700>;
			interrupts = <0x00 0x5e 0x04>;
			clocks = <0x04 0x01 0x48 0x04 0x01 0x45>;
			resets = <0x35 0x00>;
			#phy-cells = <0x01>;
			power-domains = <0x04>;
			status = "okay";
			pinctrl-0 = <0x3b>;
			pinctrl-names = "default";
			vbus-supply = <0x3c>;
			phandle = <0x36>;
		};

		usb-phy@11c70200 {
			compatible = "renesas,usb2-phy-r9a07g054", "renesas,rzg2l-usb2-phy";
			reg = <0x00 0x11c70200 0x00 0x700>;
			interrupts = <0x00 0x63 0x04>;
			clocks = <0x04 0x01 0x48 0x04 0x01 0x46>;
			resets = <0x35 0x01>;
			#phy-cells = <0x01>;
			power-domains = <0x04>;
			status = "okay";
			pinctrl-0 = <0x3d>;
			pinctrl-names = "default";
			phandle = <0x38>;
		};

		usb@11c60000 {
			compatible = "renesas,usbhs-r9a07g054", "renesas,rzg2l-usbhs";
			reg = <0x00 0x11c60000 0x00 0x10000>;
			interrupts = <0x00 0x64 0x01 0x00 0x65 0x04 0x00 0x66 0x04 0x00 0x67 0x04>;
			clocks = <0x04 0x01 0x48 0x04 0x01 0x47>;
			resets = <0x35 0x00 0x04 0x39>;
			renesas,buswait = <0x07>;
			phys = <0x36 0x03>;
			phy-names = "usb";
			power-domains = <0x04>;
			status = "disabled";
		};

		watchdog@12800800 {
			compatible = "renesas,r9a07g054-wdt", "renesas,rzg2l-wdt";
			reg = <0x00 0x12800800 0x00 0x400>;
			clocks = <0x04 0x01 0x18 0x04 0x01 0x19>;
			clock-names = "pclk", "oscclk";
			interrupts = <0x00 0x31 0x04 0x00 0x32 0x04>;
			interrupt-names = "wdt", "perrout";
			resets = <0x04 0x1e>;
			power-domains = <0x04>;
			channel,id = <0x00>;
			status = "okay";
			timeout-sec = <0x3c>;
		};

		watchdog@12800c00 {
			compatible = "renesas,r9a07g054-wdt", "renesas,rzg2l-wdt";
			reg = <0x00 0x12800c00 0x00 0x400>;
			clocks = <0x04 0x01 0x1a 0x04 0x01 0x1b>;
			clock-names = "pclk", "oscclk";
			interrupts = <0x00 0x33 0x04 0x00 0x34 0x04>;
			interrupt-names = "wdt", "perrout";
			resets = <0x04 0x1f>;
			power-domains = <0x04>;
			channel,id = <0x01>;
			status = "okay";
			timeout-sec = <0x3c>;
		};

		timer@12801400 {
			compatible = "renesas,r9a07g054-ostm", "renesas,ostm";
			reg = <0x00 0x12801400 0x00 0x400>;
			interrupts = <0x00 0x2f 0x01>;
			clocks = <0x04 0x01 0x0f>;
			resets = <0x04 0x15>;
			power-domains = <0x04>;
			status = "okay";
		};

		timer@12801800 {
			compatible = "renesas,r9a07g054-ostm", "renesas,ostm";
			reg = <0x00 0x12801800 0x00 0x400>;
			interrupts = <0x00 0x30 0x01>;
			clocks = <0x04 0x01 0x10>;
			resets = <0x04 0x16>;
			power-domains = <0x04>;
			status = "okay";
		};

		drpai@12C00000 {
			compatible = "renesas,rzv2l-drpai";
			reg = <0x00 0x13000000 0x00 0x1000000 0x00 0x12c00000 0x00 0x400000>;
			clocks = <0x04 0x01 0x61 0x04 0x01 0x62 0x04 0x01 0x63 0x04 0x01 0x64 0x04 0x01 0x65>;
			resets = <0x04 0x54>;
			power-domains = <0x04>;
			sysctrl = <0x3e>;
			clock-names = "intclk", "aclk_drp", "mclk", "dclkin", "aclk";
			interrupts = <0x00 0x1b8 0x04 0x00 0x1b9 0x04 0x00 0x1ba 0x04 0x00 0x1bb 0x04>;
			status = "disabled";
		};
	};

	thermal-zones {

		emergency {
			polling-delay = <0x3e8>;
			on-temperature = <0x1b198>;
			off-temperature = <0x17318>;
			target_cpus = <0x02>;
			status = "disabled";
		};

		cpu-thermal {
			polling-delay-passive = <0xfa>;
			polling-delay = <0x3e8>;
			thermal-sensors = <0x3f 0x00>;
			sustainable-power = <0x2cd>;

			cooling-maps {

				map0 {
					trip = <0x40>;
					cooling-device = <0x01 0x00 0x02>;
					contribution = <0x400>;
				};
			};

			trips {

				sensor-crit {
					temperature = <0x1e848>;
					hysteresis = <0x3e8>;
					type = "critical";
				};

				trip-point {
					temperature = <0x186a0>;
					hysteresis = <0x3e8>;
					type = "passive";
					phandle = <0x40>;
				};
			};
		};
	};

	timer {
		compatible = "arm,armv8-timer";
		interrupts-extended = <0x06 0x01 0x0d 0x308 0x06 0x01 0x0e 0x308 0x06 0x01 0x0b 0x308 0x06 0x01 0x0a 0x308>;
	};

	aliases {
		serial0 = "/soc/serial@1004b800";
		serial1 = "/soc/serial@1004bc00";
		serial2 = "/soc/serial@1004c000";
		serial3 = "/soc/serial@1004c400";
		i2c0 = "/soc/i2c@10058000";
		i2c1 = "/soc/i2c@10058400";
		i2c2 = "/soc/i2c@10058800";
		i2c3 = "/soc/i2c@10058c00";
		mmc0 = "/soc/mmc@11c00000";
		mmc1 = "/soc/mmc@11c10000";
		ethernet0 = "/soc/ethernet@11c20000";
	};

	chosen {
		bootargs = "rw rootwait earlycon root=/dev/mmcblk1p2 wdt_overflow=0";
		stdout-path = "serial0:115200n8";
	};

	cec-clock {
		compatible = "fixed-clock";
		#clock-cells = <0x00>;
		clock-frequency = <0xb71b00>;
	};

	clk_ext_audio {
		compatible = "fixed-clock";
		#clock-cells = <0x00>;
		clock-frequency = <0xac4400>;
		phandle = <0x21>;
	};

	sound {
		compatible = "simple-audio-card";
		simple-audio-card,name = "RZV2L-SGTL5000";
		simple-audio-card,format = "i2s";
		simple-audio-card,bitclock-master = <0x41>;
		simple-audio-card,frame-master = <0x41>;
		simple-audio-card,mclk-fs = <0x100>;
		simple-audio-card,widgets = "Microphone", "Microphone Jack", "Headphone", "Headphone Jack", "Speaker", "Speaker Ext", "Line", "Line In Jack";
		simple-audio-card,routing = "MIC_IN", "Microphone Jack", "Microphone Jack", "Mic Bias", "LINE_IN", "Line In Jack", "Headphone Jack", "HP_OUT", "Speaker Ext", "LINE_OUT";

		simple-audio-card,cpu {
			sound-dai = <0x42>;
			system-clock-frequency = <0xac4400>;
			phandle = <0x41>;
		};

		simple-audio-card,codec {
			sound-dai = <0x43>;
		};
	};

	reserved-memory {
		#address-cells = <0x02>;
		#size-cells = <0x02>;
		ranges;

		linux,cma@58000000 {
			compatible = "shared-dma-pool";
			linux,cma-default;
			reusable;
			reg = <0x00 0x58000000 0x00 0x10000000>;
			phandle = <0x37>;
		};

		linux,multimedia {
			compatible = "shared-dma-pool";
			reusable;
			reg = <0x00 0x68000000 0x00 0x8000000>;
			phandle = <0x44>;
		};
	};

	memory@48000000 {
		device_type = "memory";
		reg = <0x00 0x48000000 0x00 0x78000000>;
	};

	mmngr {
		compatible = "renesas,mmngr";
		memory-region = <0x44>;
	};

	mmngrbuf {
		compatible = "renesas,mmngrbuf";
	};

	vspm_if {
		compatible = "renesas,vspm_if";
	};

	regulator-vdd-core {
		compatible = "regulator-fixed";
		regulator-name = "fixed-1.1V";
		regulator-min-microvolt = <0x10c8e0>;
		regulator-max-microvolt = <0x10c8e0>;
		regulator-boot-on;
		regulator-always-on;
		phandle = <0x30>;
	};

	regulator0 {
		compatible = "regulator-fixed";
		regulator-name = "fixed-1.8V";
		regulator-min-microvolt = <0x1b7740>;
		regulator-max-microvolt = <0x1b7740>;
		regulator-boot-on;
		regulator-always-on;
		phandle = <0x20>;
	};

	regulator1 {
		compatible = "regulator-fixed";
		regulator-name = "fixed-3.3V";
		regulator-min-microvolt = <0x325aa0>;
		regulator-max-microvolt = <0x325aa0>;
		regulator-boot-on;
		regulator-always-on;
		phandle = <0x1f>;
	};

	regulator-dsi-switch {
		compatible = "regulator-fixed";
		regulator-name = "dsi_switch";
		gpio = <0x1c 0x15a 0x00>;
		enable-active-high;
		regulator-min-microvolt = <0x325aa0>;
		regulator-max-microvolt = <0x325aa0>;
		regulator-always-on;
		regulator-boot-on;
	};

	regulator-vccq-sdhi1 {
		compatible = "regulator-gpio";
		regulator-name = "SDHI1 VccQ";
		regulator-min-microvolt = <0x1b7740>;
		regulator-max-microvolt = <0x325aa0>;
		gpios-states = <0x01>;
		states = <0x325aa0 0x01 0x1b7740 0x00>;
	};

	1p8v {
		compatible = "regulator-fixed";
		regulator-name = "camera_vdddo";
		regulator-min-microvolt = <0x1b7740>;
		regulator-max-microvolt = <0x1b7740>;
		regulator-always-on;
		phandle = <0x19>;
	};

	2p8v {
		compatible = "regulator-fixed";
		regulator-name = "camera_vdda";
		regulator-min-microvolt = <0x2ab980>;
		regulator-max-microvolt = <0x2ab980>;
		regulator-always-on;
		phandle = <0x1a>;
	};

	1p5v {
		compatible = "regulator-fixed";
		regulator-name = "camera_vddd";
		regulator-min-microvolt = <0x16e360>;
		regulator-max-microvolt = <0x16e360>;
		regulator-always-on;
		phandle = <0x1b>;
	};

	osc25250-clk {
		compatible = "fixed-clock";
		#clock-cells = <0x00>;
		clock-frequency = <0x16e3600>;
		phandle = <0x18>;
	};

	backlight {
		compatible = "pwm-backlight";
		pwms = <0x45 0x00 0x9c40 0x00>;
		brightness-levels = <0x00 0x08 0x20 0x40 0x60 0x80 0xa0 0xc0 0xe0 0xff>;
		default-brightness-level = <0x08>;
		status = "okay";
		phandle = <0x28>;
	};

	gpio-keys {
		compatible = "gpio-keys";
		pinctrl-names = "default";

		nmi {
			interrupt-parent = <0x2e>;
			interrupts = <0x00 0x02>;
			linux,code = <0x04>;
			label = "NMI";
			debounce-interval = <0x0a>;
			wakeup-source;
		};

		user {
			interrupt-parent = <0x1c>;
			interrupts = <0x159 0x08>;
			linux,code = <0x02>;
			label = "user";
			debounce-interval = <0x0a>;
			wakeup-source;
		};
	};

	leds {
		compatible = "gpio-leds";

		led1 {
			gpios = <0x1c 0x118 0x01>;
			label = "led1";
			default-state = "on";
			linux,default-trigger = "heartbeat";
		};

		led2 {
			gpios = <0x1c 0x119 0x01>;
			label = "led2";
			default-state = "on";
			linux,default-trigger = "heartbeat";
		};
	};
};
